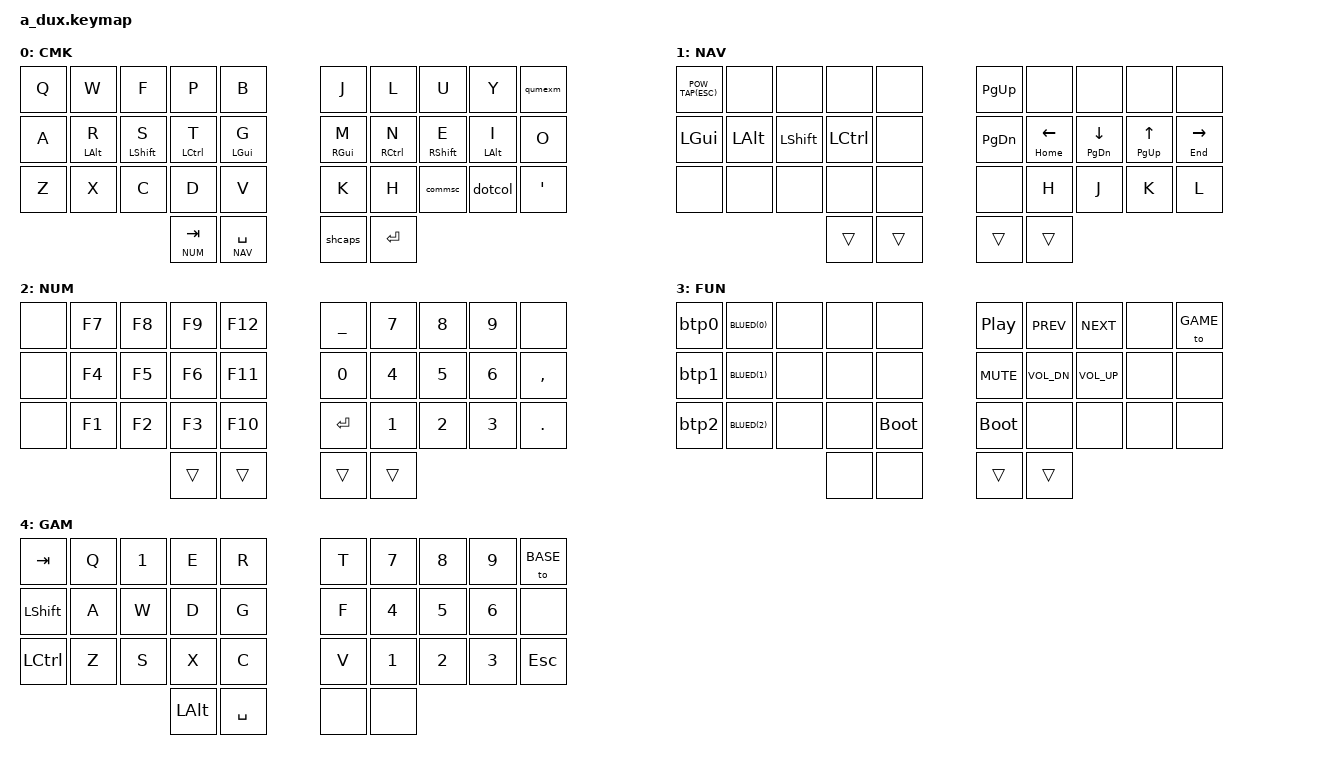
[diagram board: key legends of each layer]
/*
 * Copyright (c) 2021 The ZMK Contributors
 *
 * SPDX-License-Identifier: MIT
 */

#include <behaviors.dtsi>
#include <dt-bindings/zmk/keys.h>
#include <dt-bindings/zmk/bt.h>
#include <dt-bindings/zmk/ext_power.h>

#define U_IDLE_MS 120
#define COMBO_TERM_MS 50
#define COMBO_IDLE_MS 95

#define RESHIFT(NAME, DEFAULT, SHIFTED)          \
    NAME: NAME {                                 \
        compatible = "zmk,behavior-mod-morph";   \
        #binding-cells = <0>;                    \
        bindings = <&kp DEFAULT>, <&kp SHIFTED>; \
        mods = <MOD_LSFT>;                       \
    }

#define COMBO(NAME, POSA, POSB, OUTPUT, TERM, IDLE) \
    NAME {                                          \
        timeout-ms = <TERM>;                        \
        layers = <0>;                               \
        key-positions = <POSA POSB>;                \
        bindings = <&kp OUTPUT>;                    \
        require-prior-idle-ms = <IDLE>;             \
    }

#define BLUETOOTH_PROFILE(NAME, PROFILEN)       \
    NAME: NAME {                                \
        compatible = "zmk,behavior-mod-morph";  \
        #binding-cells = <0>;                   \
        bindings = <&bt BT_SEL PROFILEN>,       \
                   <&bt BT_CLR>;                \
        mods = <MOD_LSFT>;                      \
    }

#define BLUED(PROFILEN) &bt BT_DISC PROFILEN


#define BASE 0
#define NAV 1
#define NUM 2
#define FUN 3
#define GAME 4

/* Defined here so that the keymap can have consistent size. */
#define HRM_R &mt LALT R
#define HRM_S &mt LSHFT S
#define HRM_T &mt LCTRL T
#define HRM_G &mt LGUI G

#define HRM_M &mt RGUI M
#define HRM_N &mt RCTRL N
#define HRM_E &mt RSHFT E
#define HRM_I &mt LALT I

/* TH(umb) L(eft)|R(ight) IN|OUT */
#define TH_LOUT &lt NUM TAB
#define TH_LIN  &lt NAV SPACE
#define TH_RIN  &shcaps
#define TH_ROUT &kp ENTER

#define N_LEFT  &kk HOME LEFT
#define N_DOWN  &kk PAGE_DOWN DOWN
#define N_UP    &kk PAGE_UP UP
#define N_RIGHT &kk END RIGHT

#define POW_TAP(KEY) &powtap 0 KEY

/*
 * Helper macros to define the combos given a column coordinate, that use a key and the
 * key directly below it.
 *
 * Since these are much harder to misfire on (not possible to roll), then the idle ms is
 * set to something lower than the default.
 */
#define HIGH_COL_COMBO(NAME, XPOS, OUTPUT) COMBO(NAME, (XPOS+0), (XPOS+10), OUTPUT, COMBO_TERM_MS, COMBO_IDLE_MS)
#define LOW_COL_COMBO(NAME, XPOS, OUTPUT) COMBO(NAME, (XPOS+10), (XPOS+20), OUTPUT, COMBO_TERM_MS, COMBO_IDLE_MS)

&caps_word {
    continue-list = <UNDERSCORE MINUS BACKSPACE DELETE>;
};

&lt {
    /* require-prior-idle-ms = <100>; */
    tapping-term-ms = <250>;
    flavor = "balanced";
};

&mt {
    require-prior-idle-ms = <U_IDLE_MS>;
    tapping-term-ms = <280>;
    flavor = "balanced";
    /* TODO: Implement the positional hold-tap functionality from urob/zmk-config */
};

&sk {
    release-after-ms = <700>;
    quick-release;
    /delete-property/ ignore-modifiers;
};

/ {

    conditional_layers {
        compatible = "zmk,conditional-layers";

        function_layer {
            if-layers = <NAV NUM>;
            then-layer = <FUN>;
        };
    };

    combos {
        compatible = "zmk,combos";

        /* Vertical shape combos along the top row of the keyboard. */
        HIGH_COL_COMBO(combo_grave, 1, GRAVE);
        HIGH_COL_COMBO(combo_backslash, 2, BACKSLASH);
        HIGH_COL_COMBO(combo_underscore, 3, UNDERSCORE);
        HIGH_COL_COMBO(combo_tilde, 4, TILDE);

        HIGH_COL_COMBO(combo_equals, 5, EQUAL);
        HIGH_COL_COMBO(combo_hyphen, 6, MINUS);
        HIGH_COL_COMBO(combo_slash, 7, SLASH);
        HIGH_COL_COMBO(combo_pipe, 8, PIPE);
        
        /* Vertical shape combos along the bottom row of the keyboard. */
        LOW_COL_COMBO(combo_at, 1, AT_SIGN);
        LOW_COL_COMBO(combo_pound, 2, POUND);
        LOW_COL_COMBO(combo_dollar, 3, DOLLAR);
        LOW_COL_COMBO(combo_percent, 4, PERCENT);

        LOW_COL_COMBO(combo_caret, 5, CARET);
        LOW_COL_COMBO(combo_plus, 6, PLUS);
        LOW_COL_COMBO(combo_asterisk, 7, ASTERISK);
        LOW_COL_COMBO(combo_ampersand, 8, AMPERSAND);

        /* Not only are these a different direction from the above
         * they also have different timeout-terms to prevent mis-fires
         * on roll-over */

        /* () */
        COMBO(combo_lparen, 12, 13, LEFT_PARENTHESIS, 30, U_IDLE_MS);
        COMBO(combo_rparen, 17, 16, RIGHT_PARENTHESIS, 30, U_IDLE_MS);

        /* {} */
        COMBO(combo_lbrace, 11, 12, LEFT_BRACE, 30, U_IDLE_MS);
        COMBO(combo_rbrace, 18, 17, RIGHT_BRACE, 30, U_IDLE_MS);

        /* [] */
        COMBO(combo_lbracket, 11, 13, LEFT_BRACKET, 30, U_IDLE_MS);
        COMBO(combo_rbracket, 18, 16, RIGHT_BRACKET, 30, U_IDLE_MS);

        /* <> */
        COMBO(combo_langle, 13, 14, LESS_THAN, 20, U_IDLE_MS);
        COMBO(combo_rangle, 16, 15, GREATER_THAN, 20, U_IDLE_MS);

        /* Functional keys */
        COMBO(combo_backspace, 6, 7, BACKSPACE, COMBO_TERM_MS, 20);
        COMBO(combo_delete, 7, 8, DELETE, COMBO_TERM_MS, 30);
    };

    behaviors {
        RESHIFT(qumexm, QUESTION, EXCLAMATION);
        RESHIFT(commsc, COMMA, SEMICOLON);
        RESHIFT(dotcol, DOT, COLON);

        BLUETOOTH_PROFILE(btp0, 0);
        BLUETOOTH_PROFILE(btp1, 1);
        BLUETOOTH_PROFILE(btp2, 2);

        shcaps: shift_caps_word {
            compatible = "zmk,behavior-mod-morph";
            #binding-cells = <0>;
            bindings = <&sk LSHIFT>, <&caps_word>;
            mods = <MOD_LSFT>;
        };

        kk: key_key_hold_tap {
            compatible = "zmk,behavior-hold-tap";
            #binding-cells = <2>;
            flavor = "tap-preferred";
            tapping-term-ms = <200>;
            quick-tap-ms = <180>;
            /* require-prior-idle-ms = <U_IDLE_MS>; */
            bindings = <&kp>, <&kp>;
        };

        powtap: power_kp_hold_tap {
            compatible = "zmk,behavior-hold-tap";
            #binding-cells = <2>;
            flavor = "tap-preferred";
            tapping-term-ms = <3000>;
            require-prior-idle-ms = <1000>;
            bindings = <&soft_off>, <&kp>;
        };
    };

    keymap {
        compatible = "zmk,keymap";

        base_colemak {
            display-name = "CMK";

            bindings = <
                &kp Q     &kp W     &kp F     &kp P     &kp B     &kp J     &kp L     &kp U     &kp Y     &qumexm
                &kp A     HRM_R     HRM_S     HRM_T     HRM_G     HRM_M     HRM_N     HRM_E     HRM_I     &kp O
                &kp Z     &kp X     &kp C     &kp D     &kp V     &kp K     &kp H     &commsc   &dotcol   &kp APOS
                                              TH_LOUT   TH_LIN    TH_RIN    TH_ROUT
            >;
        };

        navigation {
            display-name = "NAV";

            bindings = <
                POW_TAP(ESC) &none     &none     &none     &none     &kp PG_UP &none     &none     &none     &none
                &kp LGUI     &kp LALT  &kp LSHFT &kp LCTRL &none     &kp PG_DN N_LEFT    N_DOWN    N_UP      N_RIGHT
                &none        &none     &none     &none     &none     &none     &kp H     &kp J     &kp K     &kp L
                                                 &trans    &trans    &trans    &trans
            >;
        };

        number {
            display-name = "NUM";

            bindings = <
                &none     &kp F7    &kp F8    &kp F9    &kp F12   &kp UNDER &kp N7    &kp N8    &kp N9    &none
                &none     &kp F4    &kp F5    &kp F6    &kp F11   &kp N0    &kp N4    &kp N5    &kp N6    &kp COMMA
                &none     &kp F1    &kp F2    &kp F3    &kp F10   &kp ENTER &kp N1    &kp N2    &kp N3    &kp DOT
                                              &trans    &trans    &trans    &trans
            >;
        };

        function {
            display-name = "FUN";

            bindings = <
                &btp0     BLUED(0)  &none     &none     &none       &kp C_PP    &kp C_PREV   &kp C_NEXT   &none   &to GAME
                &btp1     BLUED(1)  &none     &none     &none       &kp C_MUTE  &kp C_VOL_DN &kp C_VOL_UP &none   &none
                &btp2     BLUED(2)  &none     &none     &bootloader &bootloader &none        &none        &none   &none
                                              &none     &none       &trans      &trans
            >;
        };

        game {
            display-name = "GAM";

            bindings = <
                &kp TAB   &kp Q     &kp N1    &kp E     &kp R     &kp T     &kp N7    &kp N8    &kp N9    &to BASE
                &kp LSHFT &kp A     &kp W     &kp D     &kp G     &kp F     &kp N4    &kp N5    &kp N6    &none
                &kp LCTRL &kp Z     &kp S     &kp X     &kp C     &kp V     &kp N1    &kp N2    &kp N3    &kp ESC
                                              &kp LALT  &kp SPACE &none     &none
            >;
        };
    };

};
